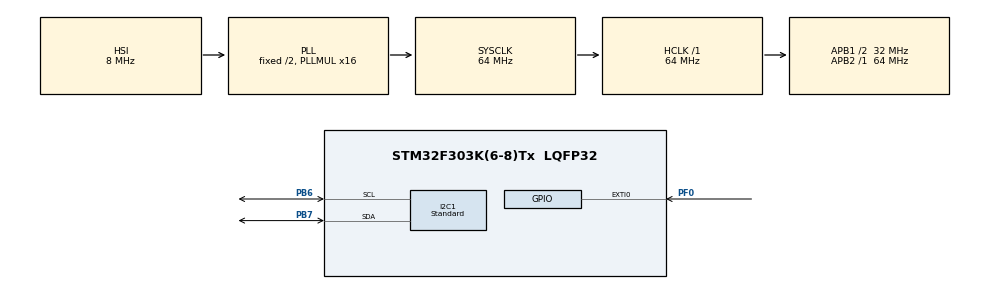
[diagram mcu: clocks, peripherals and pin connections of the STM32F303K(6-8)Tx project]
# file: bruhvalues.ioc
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I2C1.I2C_Speed_Mode=I2C_Standard
I2C1.Timing=0x2000090E
Mcu.Family=STM32F3
Mcu.Name=STM32F303K(6-8)Tx
Mcu.Package=LQFP32
NVIC.EXTI0_IRQn=true\:0\:0\:false\:false\:true\:true\:true\:true
NVIC.I2C1_EV_IRQn=true\:0\:0\:false\:false\:true\:true\:true\:true
NVIC.PriorityGroup=NVIC_PRIORITYGROUP_4
NVIC.TIM1_UP_TIM16_IRQn=true\:0\:0\:false\:false\:true\:true\:true\:true
PB6.GPIO_Pu=GPIO_PULLUP
PB6.Mode=I2C
PB6.Signal=I2C1_SCL
PB7.GPIO_Pu=GPIO_PULLUP
PB7.GPIO_Speed=GPIO_SPEED_FREQ_HIGH
PB7.Mode=I2C
PB7.Signal=I2C1_SDA
PF0\ /\ OSC_IN.Signal=GPXTI0
ProjectManager.HeapSize=0x200
ProjectManager.StackSize=0x400
ProjectManager.TargetToolchain=STM32CubeIDE
RCC.AHBFreq_Value=64000000
RCC.APB1CLKDivider=RCC_HCLK_DIV2
RCC.APB1Freq_Value=32000000
RCC.APB1TimFreq_Value=64000000
RCC.APB2Freq_Value=64000000
RCC.APB2TimFreq_Value=64000000
RCC.CortexFreq_Value=64000000
RCC.HCLKFreq_Value=64000000
RCC.HSE_VALUE=8000000
RCC.HSI_VALUE=8000000
RCC.PLLMUL=RCC_PLL_MUL16
RCC.SYSCLKFreq_VALUE=64000000
RCC.SYSCLKSourceVirtual=RCC_SYSCLKSOURCE_PLLCLK
TIM16.Period=1000
TIM16.Prescaler=63
VP_TIM16_VS_ClockSourceINT.Mode=Enable_Timer
board=custom

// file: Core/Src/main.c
/* USER CODE BEGIN Header */
/**
  ******************************************************************************
  * @file           : main.c
  * @brief          : Main program body
  ******************************************************************************
  * @attention
  *
  * Copyright (c) 2023 STMicroelectronics.
  * All rights reserved.
  *
  * This software is licensed under terms that can be found in the LICENSE file
  * in the root directory of this software component.
  * If no LICENSE file comes with this software, it is provided AS-IS.
  *
  ******************************************************************************
  */
#include "stdint.h"

/* USER CODE END Header */
#include "main.h"

/* USER CODE BEGIN Includes */

#include <string.h>

#include "mpu6050.h"

/* USER CODE END Includes */

I2C_HandleTypeDef hi2c1;

TIM_HandleTypeDef htim16;

void SystemClock_Config(void);
static void MX_GPIO_Init(void);
static void MX_I2C1_Init(void);
static void MX_TIM16_Init(void);

/* USER CODE BEGIN 0 */

float accelData[3] = {0, 0, 0};
float gyroData[3] = {0, 0, 0};

uint32_t milis = 0;

uint32_t skips = 0;

void HAL_TIM_PeriodElapsedCallback(TIM_HandleTypeDef *htim)
{
	milis++;
}

uint32_t data_ready_cnt = 0;

void HAL_GPIO_EXTI_Callback(uint16_t GPIO_Pin)
{
	// Data ready callback!
	data_ready_cnt++;
}

/* USER CODE END 0 */

int main(void)
{

  /* MCU Configuration--------------------------------------------------------*/

  /* Reset of all peripherals, Initializes the Flash interface and the Systick. */
  HAL_Init();

  /* Configure the system clock */
  SystemClock_Config();

  /* Initialize all configured peripherals */
  MX_GPIO_Init();
  MX_I2C1_Init();
  MX_TIM16_Init();
  /* USER CODE BEGIN 2 */

  HAL_TIM_Base_Start_IT(&htim16);

  if(MPUInit(&hi2c1, false))
  {
	  int a = 0;
  }

  MPUSetDataReadyInterruptEnable(true);

  /* USER CODE END 2 */

  /* Infinite loop */
  /* USER CODE BEGIN WHILE */
  while (1)
  {

	 // Perform readout once every 5 miliseconds.
	if (milis >= 40)
	{
		milis = 0;

		skips=0;

		float tmp[3] = {0, 0, 0};

		if(!MPUGetAccel(tmp))
		{
			memcpy(&accelData, &tmp, sizeof(tmp));
		}

		if(!MPUGetGyro(tmp))
		{
			memcpy(&gyroData, &tmp, sizeof(tmp));
		}

	}
	else
	{
		skips++;
	}

    /* USER CODE END WHILE */

  }
}

void SystemClock_Config(void)
{
  RCC_OscInitTypeDef RCC_OscInitStruct = {0};
  RCC_ClkInitTypeDef RCC_ClkInitStruct = {0};
  RCC_PeriphCLKInitTypeDef PeriphClkInit = {0};

  /** Initializes the RCC Oscillators according to the specified parameters
  * in the RCC_OscInitTypeDef structure.
  */
  RCC_OscInitStruct.OscillatorType = RCC_OSCILLATORTYPE_HSI;
  RCC_OscInitStruct.HSIState = RCC_HSI_ON;
  RCC_OscInitStruct.HSICalibrationValue = RCC_HSICALIBRATION_DEFAULT;
  RCC_OscInitStruct.PLL.PLLState = RCC_PLL_ON;
  RCC_OscInitStruct.PLL.PLLSource = RCC_PLLSOURCE_HSI;
  RCC_OscInitStruct.PLL.PLLMUL = RCC_PLL_MUL16;
  if (HAL_RCC_OscConfig(&RCC_OscInitStruct) != HAL_OK)
  {
    Error_Handler();
  }

  /** Initializes the CPU, AHB and APB buses clocks
  */
  RCC_ClkInitStruct.ClockType = RCC_CLOCKTYPE_HCLK|RCC_CLOCKTYPE_SYSCLK
                              |RCC_CLOCKTYPE_PCLK1|RCC_CLOCKTYPE_PCLK2;
  RCC_ClkInitStruct.SYSCLKSource = RCC_SYSCLKSOURCE_PLLCLK;
  RCC_ClkInitStruct.AHBCLKDivider = RCC_SYSCLK_DIV1;
  RCC_ClkInitStruct.APB1CLKDivider = RCC_HCLK_DIV2;
  RCC_ClkInitStruct.APB2CLKDivider = RCC_HCLK_DIV1;

  if (HAL_RCC_ClockConfig(&RCC_ClkInitStruct, FLASH_LATENCY_2) != HAL_OK)
  {
    Error_Handler();
  }
  PeriphClkInit.PeriphClockSelection = RCC_PERIPHCLK_I2C1;
  PeriphClkInit.I2c1ClockSelection = RCC_I2C1CLKSOURCE_HSI;
  if (HAL_RCCEx_PeriphCLKConfig(&PeriphClkInit) != HAL_OK)
  {
    Error_Handler();
  }
}

static void MX_I2C1_Init(void)
{

  hi2c1.Instance = I2C1;
  hi2c1.Init.Timing = 0x2000090E;
  hi2c1.Init.OwnAddress1 = 0;
  hi2c1.Init.AddressingMode = I2C_ADDRESSINGMODE_7BIT;
  hi2c1.Init.DualAddressMode = I2C_DUALADDRESS_DISABLE;
  hi2c1.Init.OwnAddress2 = 0;
  hi2c1.Init.OwnAddress2Masks = I2C_OA2_NOMASK;
  hi2c1.Init.GeneralCallMode = I2C_GENERALCALL_DISABLE;
  hi2c1.Init.NoStretchMode = I2C_NOSTRETCH_DISABLE;
  if (HAL_I2C_Init(&hi2c1) != HAL_OK)
  {
    Error_Handler();
  }

  /** Configure Analogue filter
  */
  if (HAL_I2CEx_ConfigAnalogFilter(&hi2c1, I2C_ANALOGFILTER_ENABLE) != HAL_OK)
  {
    Error_Handler();
  }

  /** Configure Digital filter
  */
  if (HAL_I2CEx_ConfigDigitalFilter(&hi2c1, 0) != HAL_OK)
  {
    Error_Handler();
  }

}

static void MX_TIM16_Init(void)
{

  htim16.Instance = TIM16;
  htim16.Init.Prescaler = 63;
  htim16.Init.CounterMode = TIM_COUNTERMODE_UP;
  htim16.Init.Period = 1000;
  htim16.Init.ClockDivision = TIM_CLOCKDIVISION_DIV1;
  htim16.Init.RepetitionCounter = 0;
  htim16.Init.AutoReloadPreload = TIM_AUTORELOAD_PRELOAD_DISABLE;
  if (HAL_TIM_Base_Init(&htim16) != HAL_OK)
  {
    Error_Handler();
  }

}

static void MX_GPIO_Init(void)
{
  GPIO_InitTypeDef GPIO_InitStruct = {0};

  /* GPIO Ports Clock Enable */
  __HAL_RCC_GPIOF_CLK_ENABLE();
  __HAL_RCC_GPIOB_CLK_ENABLE();

  /*Configure GPIO pin : PF0 */
  GPIO_InitStruct.Pin = GPIO_PIN_0;
  GPIO_InitStruct.Mode = GPIO_MODE_IT_RISING;
  GPIO_InitStruct.Pull = GPIO_NOPULL;
  HAL_GPIO_Init(GPIOF, &GPIO_InitStruct);

  /* EXTI interrupt init*/
  HAL_NVIC_SetPriority(EXTI0_IRQn, 0, 0);
  HAL_NVIC_EnableIRQ(EXTI0_IRQn);

}

void Error_Handler(void)
{
  __disable_irq();
  while (1)
  {
  }
}
